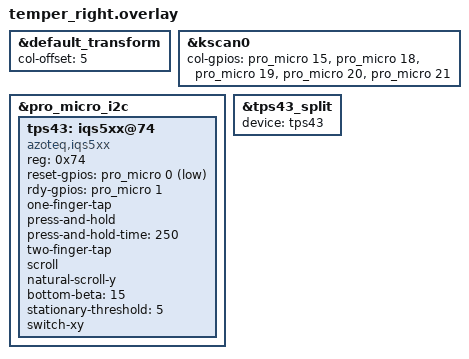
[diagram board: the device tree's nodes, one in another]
/*
 * Copyright (c) 2020 Pete Johanson
 *
 * SPDX-License-Identifier: MIT
 */

#include "temper.dtsi"
#include <dt-bindings/zmk/matrix_transform.h>

&default_transform {
    col-offset = <5>;
};

&kscan0 {
    col-gpios
        = <&pro_micro 15 GPIO_ACTIVE_HIGH>
        , <&pro_micro 18 GPIO_ACTIVE_HIGH>
        , <&pro_micro 19 GPIO_ACTIVE_HIGH>
        , <&pro_micro 20 GPIO_ACTIVE_HIGH>
        , <&pro_micro 21 GPIO_ACTIVE_HIGH>
        ;
};

&pro_micro_i2c {
    status = "okay";

    tps43: iqs5xx@74 {
        status = "okay";
        compatible = "azoteq,iqs5xx";
        reg = <0x74>;

        reset-gpios = <&pro_micro 0 GPIO_ACTIVE_LOW>;
        rdy-gpios = <&pro_micro 1 GPIO_ACTIVE_HIGH>;

        one-finger-tap;
        press-and-hold;
        press-and-hold-time = <250>;
        two-finger-tap;

        scroll;
        natural-scroll-y;

        bottom-beta = <15>;
        stationary-threshold = <5>;

        switch-xy;
        // flip-x;
        // flip-y;
    };
};

&tps43_split {
    device = <&tps43>;
};
